# EFFECTS register map
File version: 1.0
Registers are 32-bit, read-write, no defined reset value unless marked. A register's access mark holds for its fields unless they carry their own. Offsets are from the block's base; lines under a group give offsets from that group; [hi:lo] are bit positions; {n}, {i} and the like mark numbered series; 'fields as' and 'values as' point back to an identical list; <NAME> marks a mode.

## Memory map
0x40000000 WRITES
0x40001000 READS

## WRITES
Base 0x40000000
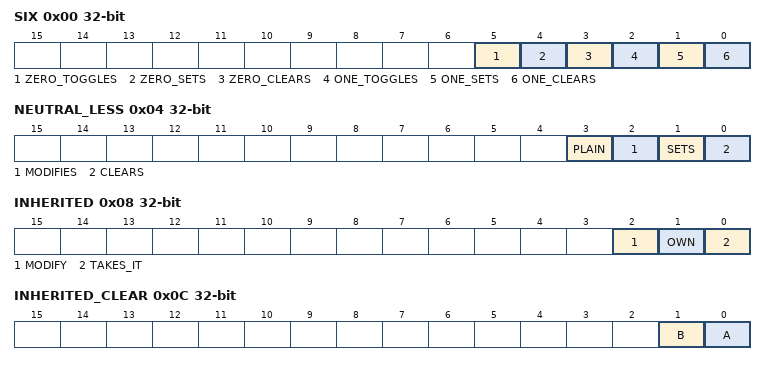
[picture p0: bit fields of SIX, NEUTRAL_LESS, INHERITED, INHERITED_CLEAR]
0x00 SIX — The six write effects that have a value without effect.
  [5] ZERO_TOGGLES write-0-toggles, [4] ZERO_SETS write-0-sets, [3] ZERO_CLEARS write-0-clears, [2] ONE_TOGGLES write-1-toggles, [1] ONE_SETS write-1-sets, [0] ONE_CLEARS write-1-clears
0x04 NEUTRAL_LESS — Write effects that have no value without effect: declared without them, and warned.
  [3] PLAIN
  [2] MODIFIES — The default, stated: nothing is lost.
  [1] SETS write-sets
  [0] CLEARS write-clears — Any write clears it.
0x08 INHERITED write-1-clears — The register states oneToClear, which its fields take unless they state their own.
  [2] MODIFY — States modify over the register's effect.
  [1] OWN write-0-sets
  [0] TAKES_IT
0x0C INHERITED_CLEAR write-clears — The register states clear, which has no declaration: its field without an effect of its own takes it, and is warned.
  [1] B write-1-sets, [0] A

## READS
Base 0x40001000
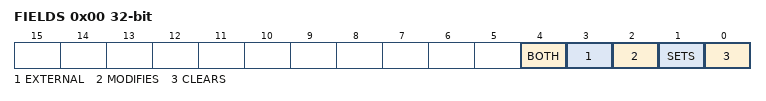
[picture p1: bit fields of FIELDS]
0x00 FIELDS — The read actions of fields.
  [4] BOTH write-1-clears read-clears — A read action and a write effect.
  [3] EXTERNAL read-has-side-effects
  [2] MODIFIES read-modifies
  [1] SETS read-sets
  [0] CLEARS read-clears
0x04 CLEARS read-clears
0x08 SETS read-sets
0x0C MODIFIES read-modifies
0x10 EXTERNAL read-has-side-effects
